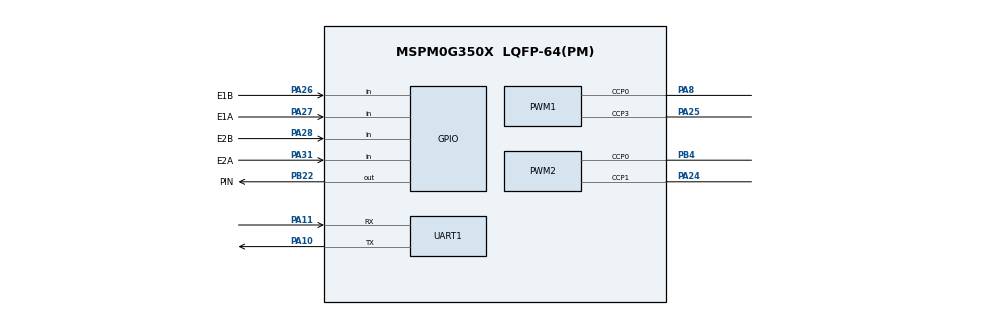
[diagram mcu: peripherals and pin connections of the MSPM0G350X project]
/**
 * @cliArgs --device "MSPM0G350X" --part "Default" --package "LQFP-64(PM)" --product "mspm0_sdk@2.02.00.05"
 * @versions {"tool":"1.21.0+3721"}
 */

/**
 * Import the modules used in this configuration.
 */
const GPIO   = scripting.addModule("/ti/driverlib/GPIO", {}, false);
const GPIO1  = GPIO.addInstance();
const GPIO2  = GPIO.addInstance();
const PWM    = scripting.addModule("/ti/driverlib/PWM", {}, false);
const PWM1   = PWM.addInstance();
const PWM2   = PWM.addInstance();
const SYSCTL = scripting.addModule("/ti/driverlib/SYSCTL");
const TIMER  = scripting.addModule("/ti/driverlib/TIMER", {}, false);
const TIMER1 = TIMER.addInstance();
const UART   = scripting.addModule("/ti/driverlib/UART", {}, false);
const UART1  = UART.addInstance();

/**
 * Write custom configuration values to the imported modules.
 */
const divider9       = system.clockTree["UDIV"];
divider9.divideValue = 2;

const mux4       = system.clockTree["EXHFMUX"];
mux4.inputSelect = "EXHFMUX_XTAL";

const mux8       = system.clockTree["HSCLKMUX"];
mux8.inputSelect = "HSCLKMUX_SYSPLL2X";

const mux12       = system.clockTree["SYSPLLMUX"];
mux12.inputSelect = "zSYSPLLMUX_HFCLK";

const pinFunction4        = system.clockTree["HFXT"];
pinFunction4.inputFreq    = 40;
pinFunction4.enable       = true;
pinFunction4.HFCLKMonitor = true;
pinFunction4.HFXTStartup  = 20;

GPIO1.$name                          = "LED";
GPIO1.associatedPins[0].$name        = "PIN";
GPIO1.associatedPins[0].ioStructure  = "SD";
GPIO1.associatedPins[0].assignedPort = "PORTB";
GPIO1.associatedPins[0].assignedPin  = "22";
GPIO1.associatedPins[0].pin.$assign  = "PB22";

const Board = scripting.addModule("/ti/driverlib/Board", {}, false);

GPIO2.$name                               = "ENCODER";
GPIO2.port                                = "PORTA";
GPIO2.associatedPins.create(4);
GPIO2.associatedPins[0].$name             = "E1A";
GPIO2.associatedPins[0].direction         = "INPUT";
GPIO2.associatedPins[0].interruptEn       = true;
GPIO2.associatedPins[0].assignedPin       = "27";
GPIO2.associatedPins[0].polarity          = "RISE";
GPIO2.associatedPins[0].interruptPriority = "0";
GPIO2.associatedPins[0].pin.$assign       = "PA27";
GPIO2.associatedPins[1].$name             = "E1B";
GPIO2.associatedPins[1].direction         = "INPUT";
GPIO2.associatedPins[1].interruptEn       = true;
GPIO2.associatedPins[1].polarity          = "RISE";
GPIO2.associatedPins[1].interruptPriority = "0";
GPIO2.associatedPins[1].assignedPin       = "26";
GPIO2.associatedPins[1].pin.$assign       = "PA26";
GPIO2.associatedPins[2].$name             = "E2A";
GPIO2.associatedPins[2].direction         = "INPUT";
GPIO2.associatedPins[2].assignedPin       = "31";
GPIO2.associatedPins[2].interruptEn       = true;
GPIO2.associatedPins[2].polarity          = "RISE";
GPIO2.associatedPins[2].interruptPriority = "0";
GPIO2.associatedPins[2].pin.$assign       = "PA31";
GPIO2.associatedPins[3].$name             = "E2B";
GPIO2.associatedPins[3].direction         = "INPUT";
GPIO2.associatedPins[3].assignedPin       = "28";
GPIO2.associatedPins[3].interruptEn       = true;
GPIO2.associatedPins[3].polarity          = "RISE";
GPIO2.associatedPins[3].interruptPriority = "0";
GPIO2.associatedPins[3].pin.$assign       = "PA28";

PWM1.timerStartTimer                    = true;
PWM1.$name                              = "PWM_0";
PWM1.ccIndex                            = [0,3];
PWM1.timerCount                         = 10000;
PWM1.clockDivider                       = 8;
PWM1.peripheral.$assign                 = "TIMA0";
PWM1.peripheral.ccp3Pin.$assign         = "PA25";
PWM1.peripheral.ccp0Pin.$assign         = "PA8";
PWM1.PWM_CHANNEL_3.$name                = "ti_driverlib_pwm_PWMTimerCC1";
PWM1.ccp3PinConfig.$name                = "ti_driverlib_gpio_GPIOPinGeneric2";
PWM1.ccp3PinConfig.direction            = scripting.forceWrite("OUTPUT");
PWM1.ccp3PinConfig.hideOutputInversion  = scripting.forceWrite(false);
PWM1.ccp3PinConfig.onlyInternalResistor = scripting.forceWrite(false);
PWM1.ccp3PinConfig.passedPeripheralType = scripting.forceWrite("Digital");
PWM1.PWM_CHANNEL_0.$name                = "ti_driverlib_pwm_PWMTimerCC0";
PWM1.ccp0PinConfig.$name                = "ti_driverlib_gpio_GPIOPinGeneric6";

PWM2.$name                              = "PWM_1";
PWM2.clockDivider                       = 8;
PWM2.timerStartTimer                    = true;
PWM2.timerCount                         = 10000;
PWM2.peripheral.$assign                 = "TIMA1";
PWM2.peripheral.ccp0Pin.$assign         = "PB4";
PWM2.peripheral.ccp1Pin.$assign         = "PA24";
PWM2.PWM_CHANNEL_0.$name                = "ti_driverlib_pwm_PWMTimerCC2";
PWM2.PWM_CHANNEL_1.$name                = "ti_driverlib_pwm_PWMTimerCC3";
PWM2.ccp0PinConfig.$name                = "ti_driverlib_gpio_GPIOPinGeneric4";
PWM2.ccp0PinConfig.direction            = scripting.forceWrite("OUTPUT");
PWM2.ccp0PinConfig.hideOutputInversion  = scripting.forceWrite(false);
PWM2.ccp0PinConfig.onlyInternalResistor = scripting.forceWrite(false);
PWM2.ccp0PinConfig.passedPeripheralType = scripting.forceWrite("Digital");
PWM2.ccp1PinConfig.$name                = "ti_driverlib_gpio_GPIOPinGeneric5";
PWM2.ccp1PinConfig.direction            = scripting.forceWrite("OUTPUT");
PWM2.ccp1PinConfig.hideOutputInversion  = scripting.forceWrite(false);
PWM2.ccp1PinConfig.onlyInternalResistor = scripting.forceWrite(false);
PWM2.ccp1PinConfig.passedPeripheralType = scripting.forceWrite("Digital");

SYSCTL.forceDefaultClkConfig = true;
SYSCTL.clockTreeEn           = true;
SYSCTL.validateClkStatus     = true;

TIMER1.$name              = "TIMER_0";
TIMER1.timerPeriod        = "5 ms";
TIMER1.timerMode          = "PERIODIC";
TIMER1.timerStartTimer    = true;
TIMER1.interrupts         = ["ZERO"];
TIMER1.timerClkDiv        = 4;
TIMER1.interruptPriority  = "2";
TIMER1.peripheral.$assign = "TIMG0";

UART1.$name                        = "UART_0";
UART1.targetBaudRate               = 115200;
UART1.peripheral.$assign           = "UART0";
UART1.peripheral.rxPin.$assign     = "PA11";
UART1.peripheral.txPin.$assign     = "PA10";
UART1.txPinConfig.$name            = "ti_driverlib_gpio_GPIOPinGeneric0";
UART1.txPinConfig.enableConfig     = true;
UART1.txPinConfig.internalResistor = "PULL_UP";
UART1.rxPinConfig.$name            = "ti_driverlib_gpio_GPIOPinGeneric1";
UART1.rxPinConfig.enableConfig     = true;
UART1.rxPinConfig.internalResistor = "PULL_UP";

/**
 * Pinmux solution for unlocked pins/peripherals. This ensures that minor changes to the automatic solver in a future
 * version of the tool will not impact the pinmux you originally saw.  These lines can be completely deleted in order to
 * re-solve from scratch.
 */
pinFunction4.peripheral.$suggestSolution           = "SYSCTL";
pinFunction4.peripheral.hfxInPin.$suggestSolution  = "PA5";
pinFunction4.peripheral.hfxOutPin.$suggestSolution = "PA6";
Board.peripheral.$suggestSolution                  = "DEBUGSS";
Board.peripheral.swclkPin.$suggestSolution         = "PA20";
Board.peripheral.swdioPin.$suggestSolution         = "PA19";
